# EFR32FG1V131F256GM48 register map
File version: 3.0.0
CPU: CM4 r0p1, little endian, MPU, FPU, 3 interrupt priority bits
Registers are 32-bit, read-write, reset 0x0 unless marked. A register's access mark holds for its fields unless they carry their own. Offsets are from the block's base; [hi:lo] are bit positions; {n}, {i} and the like mark numbered series; 'fields as' and 'values as' point back to an identical list.

## WDOG0
Base 0x40052000
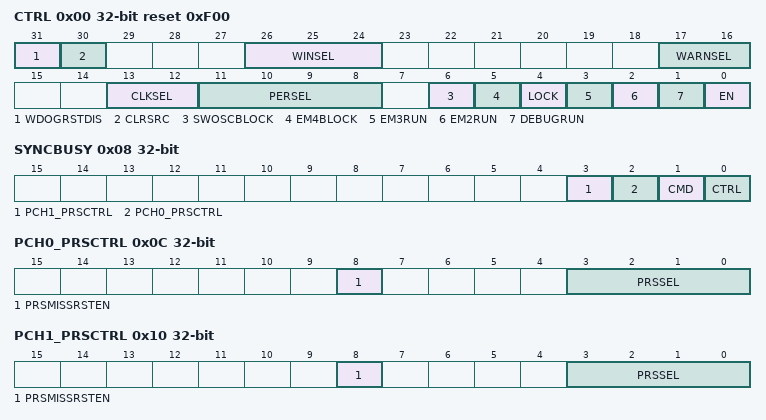
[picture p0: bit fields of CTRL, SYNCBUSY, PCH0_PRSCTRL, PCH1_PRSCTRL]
0x00 CTRL reset 0xF00 — Control Register
  [31] WDOGRSTDIS — Watchdog Reset Disable
  [30] CLRSRC — Watchdog Clear Source
  [26:24] WINSEL — Watchdog Illegal Window Select
  [17:16] WARNSEL — Watchdog Timeout Period Select
  [13:12] CLKSEL — Watchdog Clock Select
    0=ULFRCO; 1=LFRCO; 2=LFXO
  [11:8] PERSEL — Watchdog Timeout Period Select
  [6] SWOSCBLOCK — Software Oscillator Disable Block
  [5] EM4BLOCK — Energy Mode 4 Block
  [4] LOCK — Configuration Lock
  [3] EM3RUN — Energy Mode 3 Run Enable
  [2] EM2RUN — Energy Mode 2 Run Enable
  [1] DEBUGRUN — Debug Mode Run Enable
  [0] EN — Watchdog Timer Enable
0x04 CMD wo — Command Register
  [0] CLEAR — Watchdog Timer Clear
0x08 SYNCBUSY ro — Synchronization Busy Register
  [3] PCH1_PRSCTRL — PCH1_PRSCTRL Register Busy
  [2] PCH0_PRSCTRL — PCH0_PRSCTRL Register Busy
  [1] CMD — CMD Register Busy
  [0] CTRL — CTRL Register Busy
0x0C PCH0_PRSCTRL — PRS Control Register
  [8] PRSMISSRSTEN — PRS Missing Event Will Trigger a Watchdog Reset
  [3:0] PRSSEL — PRS Channel PRS Select
    {v}=PRSCH{v} (PRS Channel {v} selected as input) (v=0..11)
0x10 PCH1_PRSCTRL — PRS Control Register
  fields as PCH0_PRSCTRL
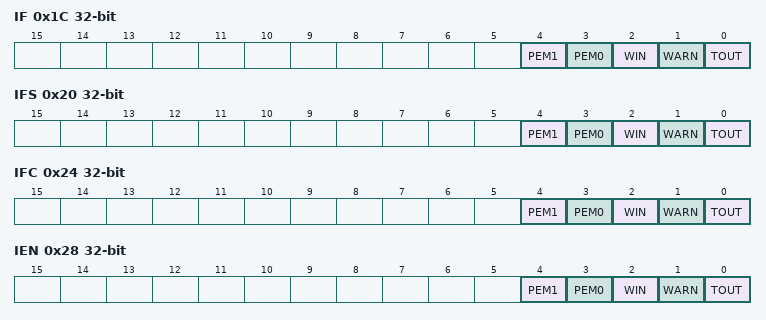
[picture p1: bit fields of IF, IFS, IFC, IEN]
0x1C IF ro — Watchdog Interrupt Flags
  [4] PEM1 — PRS Channel One Event Missing Interrupt Flag
  [3] PEM0 — PRS Channel Zero Event Missing Interrupt Flag
  [2] WIN — WDOG Window Interrupt Flag
  [1] WARN — WDOG Warning Timeout Interrupt Flag
  [0] TOUT — WDOG Timeout Interrupt Flag
0x20 IFS wo — Interrupt Flag Set Register
  [4] PEM1 — Set PEM1 Interrupt Flag
  [3] PEM0 — Set PEM0 Interrupt Flag
  [2] WIN — Set WIN Interrupt Flag
  [1] WARN — Set WARN Interrupt Flag
  [0] TOUT — Set TOUT Interrupt Flag
0x24 IFC wo — Interrupt Flag Clear Register
  [4] PEM1 — Clear PEM1 Interrupt Flag
  [3] PEM0 — Clear PEM0 Interrupt Flag
  [2] WIN — Clear WIN Interrupt Flag
  [1] WARN — Clear WARN Interrupt Flag
  [0] TOUT — Clear TOUT Interrupt Flag
0x28 IEN — Interrupt Enable Register
  [4] PEM1 — PEM1 Interrupt Enable
  [3] PEM0 — PEM0 Interrupt Enable
  [2] WIN — WIN Interrupt Enable
  [1] WARN — WARN Interrupt Enable
  [0] TOUT — TOUT Interrupt Enable

## AGC — Auto gain controller
Base 0x40087000
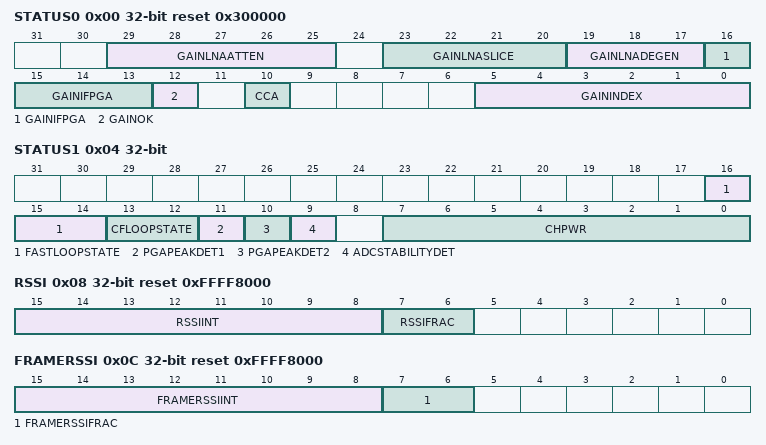
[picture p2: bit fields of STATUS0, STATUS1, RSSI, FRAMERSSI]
0x00 STATUS0 ro reset 0x300000
  [29:25] GAINLNAATTEN, [23:20] GAINLNASLICE, [19:17] GAINLNADEGEN, [16:13] GAINIFPGA, [12] GAINOK, [10] CCA, [5:0] GAININDEX
0x04 STATUS1 ro
  [16:14] FASTLOOPSTATE, [13:12] CFLOOPSTATE, [11] PGAPEAKDET1, [10] PGAPEAKDET2, [9] ADCSTABILITYDET, [7:0] CHPWR
0x08 RSSI ro reset 0xFFFF8000
  [15:8] RSSIINT, [7:6] RSSIFRAC
0x0C FRAMERSSI ro reset 0xFFFF8000
  [15:8] FRAMERSSIINT, [7:6] FRAMERSSIFRAC
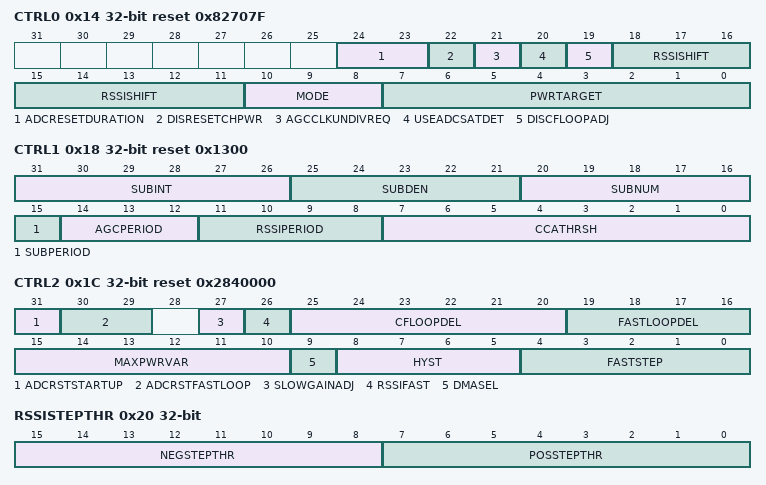
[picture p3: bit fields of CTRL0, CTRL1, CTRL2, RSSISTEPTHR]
0x14 CTRL0 reset 0x82707F
  [24:23] ADCRESETDURATION, [22] DISRESETCHPWR, [21] AGCCLKUNDIVREQ, [20] USEADCSATDET, [19] DISCFLOOPADJ, [18:11] RSSISHIFT, [10:8] MODE, [7:0] PWRTARGET
0x18 CTRL1 reset 0x1300
  [31:26] SUBINT, [25:21] SUBDEN, [20:16] SUBNUM, [15] SUBPERIOD, [14:12] AGCPERIOD, [11:8] RSSIPERIOD, [7:0] CCATHRSH
0x1C CTRL2 reset 0x2840000
  [31] ADCRSTSTARTUP, [30:29] ADCRSTFASTLOOP, [27] SLOWGAINADJ, [26] RSSIFAST, [25:20] CFLOOPDEL, [19:16] FASTLOOPDEL, [15:10] MAXPWRVAR, [9] DMASEL, [8:5] HYST, [4:0] FASTSTEP
0x20 RSSISTEPTHR
  [15:8] NEGSTEPTHR, [7:0] POSSTEPTHR
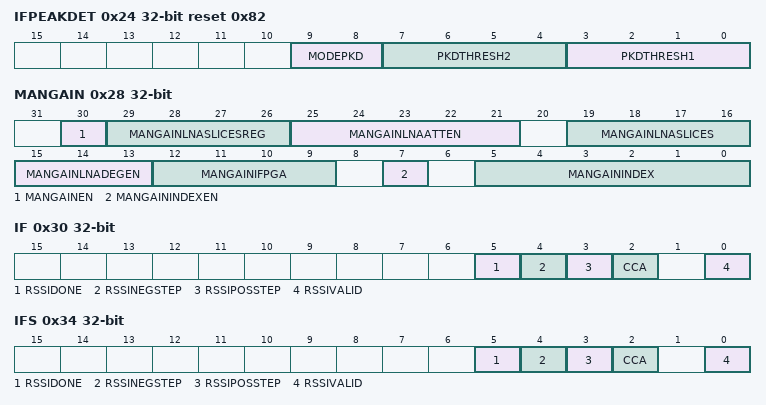
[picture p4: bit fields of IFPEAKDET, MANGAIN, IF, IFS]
0x24 IFPEAKDET reset 0x82
  [9:8] MODEPKD, [7:4] PKDTHRESH2, [3:0] PKDTHRESH1
0x28 MANGAIN
  [30] MANGAINEN, [29:26] MANGAINLNASLICESREG, [25:21] MANGAINLNAATTEN, [19:16] MANGAINLNASLICES, [15:13] MANGAINLNADEGEN, [12:9] MANGAINIFPGA, [7] MANGAININDEXEN, [5:0] MANGAININDEX
0x30 IF ro
  [5] RSSIDONE, [4] RSSINEGSTEP, [3] RSSIPOSSTEP, [2] CCA, [0] RSSIVALID
0x34 IFS wo
  fields as IF
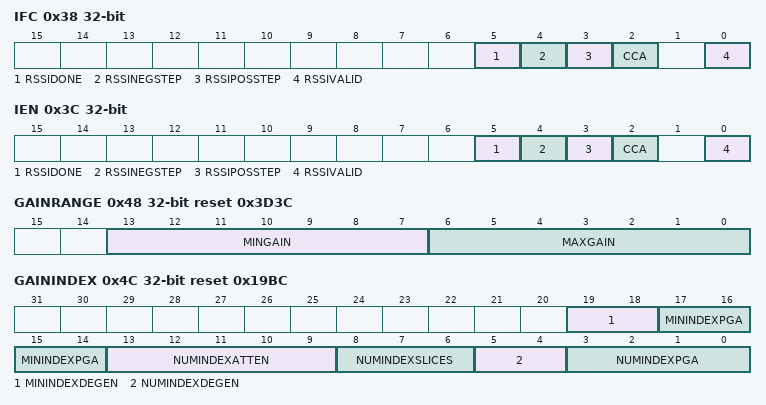
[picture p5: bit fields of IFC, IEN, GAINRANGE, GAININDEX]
0x38 IFC wo
  fields as IF
0x3C IEN
  fields as IF
0x40 CMD wo
  [0] RSSISTART
0x48 GAINRANGE reset 0x3D3C
  [13:7] MINGAIN, [6:0] MAXGAIN
0x4C GAININDEX reset 0x19BC
  [19:18] MININDEXDEGEN, [17:14] MININDEXPGA, [13:9] NUMINDEXATTEN, [8:6] NUMINDEXSLICES, [5:4] NUMINDEXDEGEN, [3:0] NUMINDEXPGA
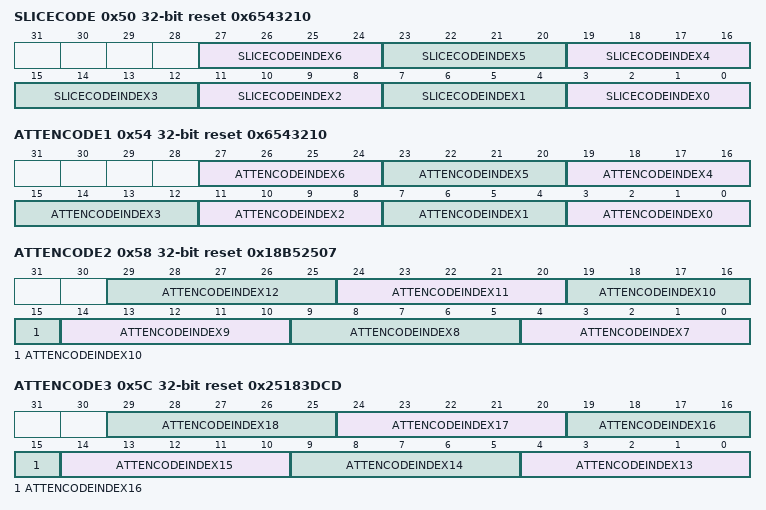
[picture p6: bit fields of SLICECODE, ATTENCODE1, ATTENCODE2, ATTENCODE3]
0x50 SLICECODE reset 0x6543210 (reset mask 0xFFFFF)
  [4n+3:4n] SLICECODEINDEX{n} (n=0..6)
0x54 ATTENCODE1 reset 0x6543210
  [4n+3:4n] ATTENCODEINDEX{n} (n=0..6)
0x58 ATTENCODE2 reset 0x18B52507
  [5n-31:5n-35] ATTENCODEINDEX{n} (n=7..12)
0x5C ATTENCODE3 reset 0x25183DCD
  [5n-61:5n-65] ATTENCODEINDEX{n} (n=13..18)
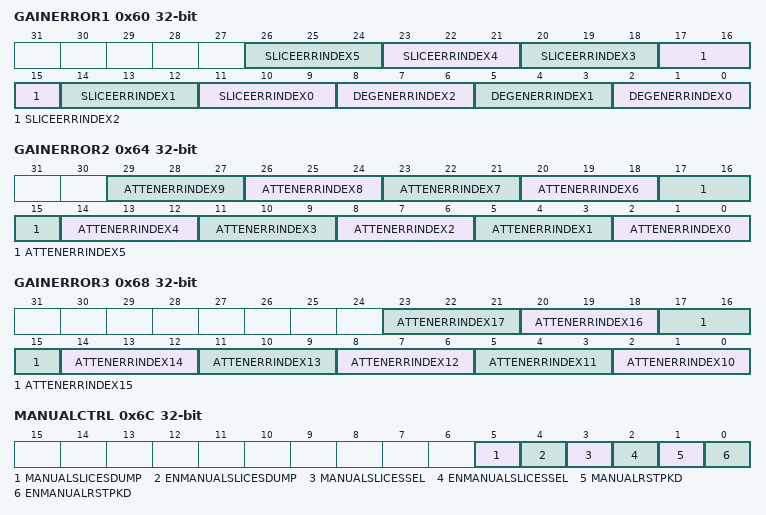
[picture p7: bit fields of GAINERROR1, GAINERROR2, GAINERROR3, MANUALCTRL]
0x60 GAINERROR1
  [3n+11:3n+9] SLICEERRINDEX{n} (n=0..5), [8:6] DEGENERRINDEX2, [5:3] DEGENERRINDEX1, [2:0] DEGENERRINDEX0
0x64 GAINERROR2
  [3n+2:3n] ATTENERRINDEX{n} (n=0..9)
0x68 GAINERROR3
  [3n-28:3n-30] ATTENERRINDEX{n} (n=10..17)
0x6C MANUALCTRL
  [5] MANUALSLICESDUMP, [4] ENMANUALSLICESDUMP, [3] MANUALSLICESSEL, [2] ENMANUALSLICESSEL, [1] MANUALRSTPKD, [0] ENMANUALRSTPKD
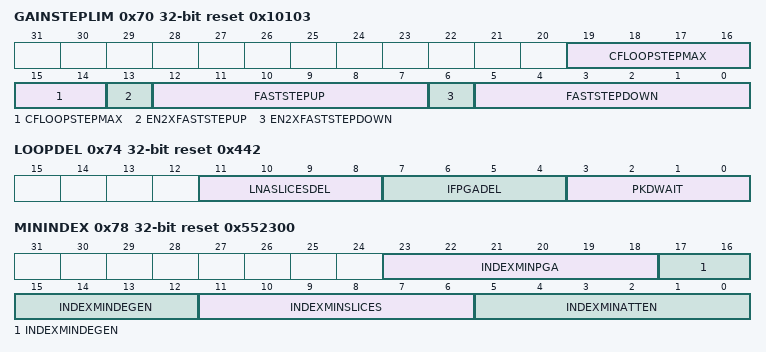
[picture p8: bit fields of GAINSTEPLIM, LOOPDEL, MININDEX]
0x70 GAINSTEPLIM reset 0x10103
  [19:14] CFLOOPSTEPMAX, [13] EN2XFASTSTEPUP, [12:7] FASTSTEPUP, [6] EN2XFASTSTEPDOWN, [5:0] FASTSTEPDOWN
0x74 LOOPDEL reset 0x442
  [11:8] LNASLICESDEL, [7:4] IFPGADEL, [3:0] PKDWAIT
0x78 MININDEX reset 0x552300
  [23:18] INDEXMINPGA, [17:12] INDEXMINDEGEN, [11:6] INDEXMINSLICES, [5:0] INDEXMINATTEN

## AGC_CLR — Auto gain controller
Base 0x44087000
Same registers: AGC_SET 0x46087000
Registers as AGC; these are added or differ:
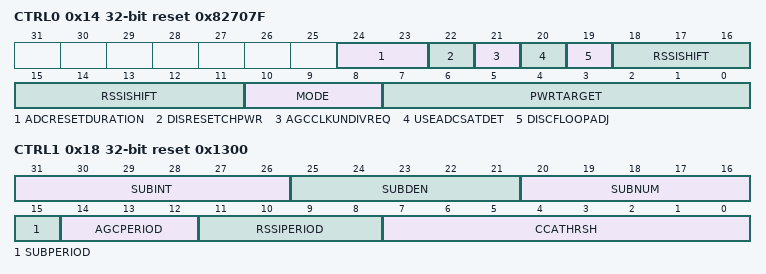
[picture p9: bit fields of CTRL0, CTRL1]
0x14 CTRL0 reset 0x82707F
  [24:23] ADCRESETDURATION, [22] DISRESETCHPWR, [21] AGCCLKUNDIVREQ, [20] USEADCSATDET, [19] DISCFLOOPADJ, [18:11] RSSISHIFT, [10:8] MODE, [7:0] PWRTARGET
0x18 CTRL1 reset 0x1300
  [31:26] SUBINT, [25:21] SUBDEN, [20:16] SUBNUM, [15] SUBPERIOD, [14:12] AGCPERIOD, [11:8] RSSIPERIOD, [7:0] CCATHRSH
